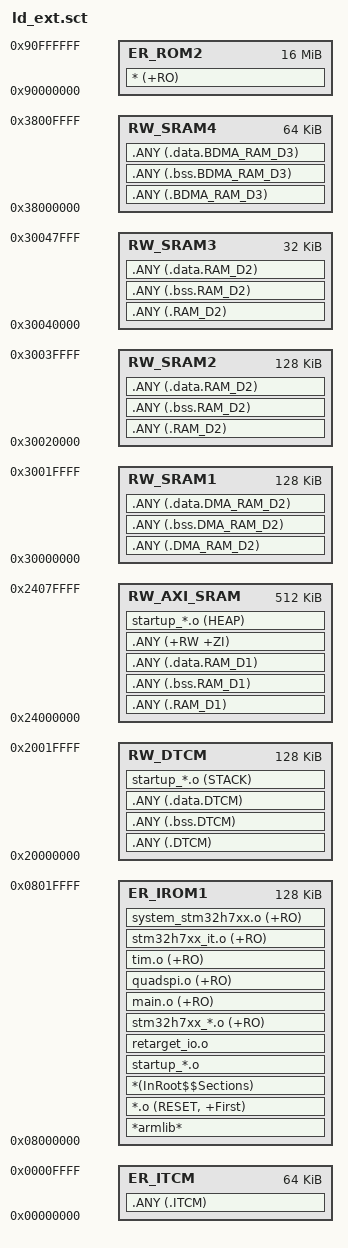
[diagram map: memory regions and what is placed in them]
LR_IROM1 0x08000000 0x20000 {
  ER_IROM1 0x08000000 0x20000 {
    ; 初始化 QUSDSPI 前使用的代码，需放在内部 FLASH

    ; ARM C lib
    *armlib*

    *.o (RESET, +First)
    *(InRoot$$Sections)

    ; startup
    startup_*.o

    retarget_io.o

    ; stm32 hal
    stm32h7xx_*.o (+RO)

    ; CubeMX
    main.o (+RO)
    quadspi.o (+RO)
    tim.o (+RO)
    stm32h7xx_it.o (+RO)
    system_stm32h7xx.o (+RO)
  }
  RW_DTCM 0x20000000 0x20000 {
    .ANY (.DTCM)
    .ANY (.bss.DTCM)
    .ANY (.data.DTCM)
    startup_*.o (STACK)
  }
  RW_AXI_SRAM 0x24000000 0x80000 {
    .ANY (.RAM_D1)
    .ANY (.bss.RAM_D1)
    .ANY (.data.RAM_D1)
    .ANY (+RW +ZI)
    startup_*.o (HEAP)
  }
  RW_SRAM1 0x30000000 0x20000 {
    .ANY (.DMA_RAM_D2)
    .ANY (.bss.DMA_RAM_D2)
    .ANY (.data.DMA_RAM_D2)
  }
  RW_SRAM2 0x30020000 0x20000 {
    .ANY (.RAM_D2)
    .ANY (.bss.RAM_D2)
    .ANY (.data.RAM_D2)
  }
  RW_SRAM3 0x30040000 0x8000 {
    .ANY (.RAM_D2)
    .ANY (.bss.RAM_D2)
    .ANY (.data.RAM_D2)
  }
  RW_SRAM4 0x38000000 0x10000 {
    .ANY (.BDMA_RAM_D3)
    .ANY (.bss.BDMA_RAM_D3)
    .ANY (.data.BDMA_RAM_D3)
  }
}

LR_ROM2 0x90000000 0x1000000 {
  ER_ROM2 0x90000000 0x1000000 {
    * (+RO)
  }
  ER_ITCM 0x00000000 0x10000 {
    .ANY (.ITCM)
  }
}
